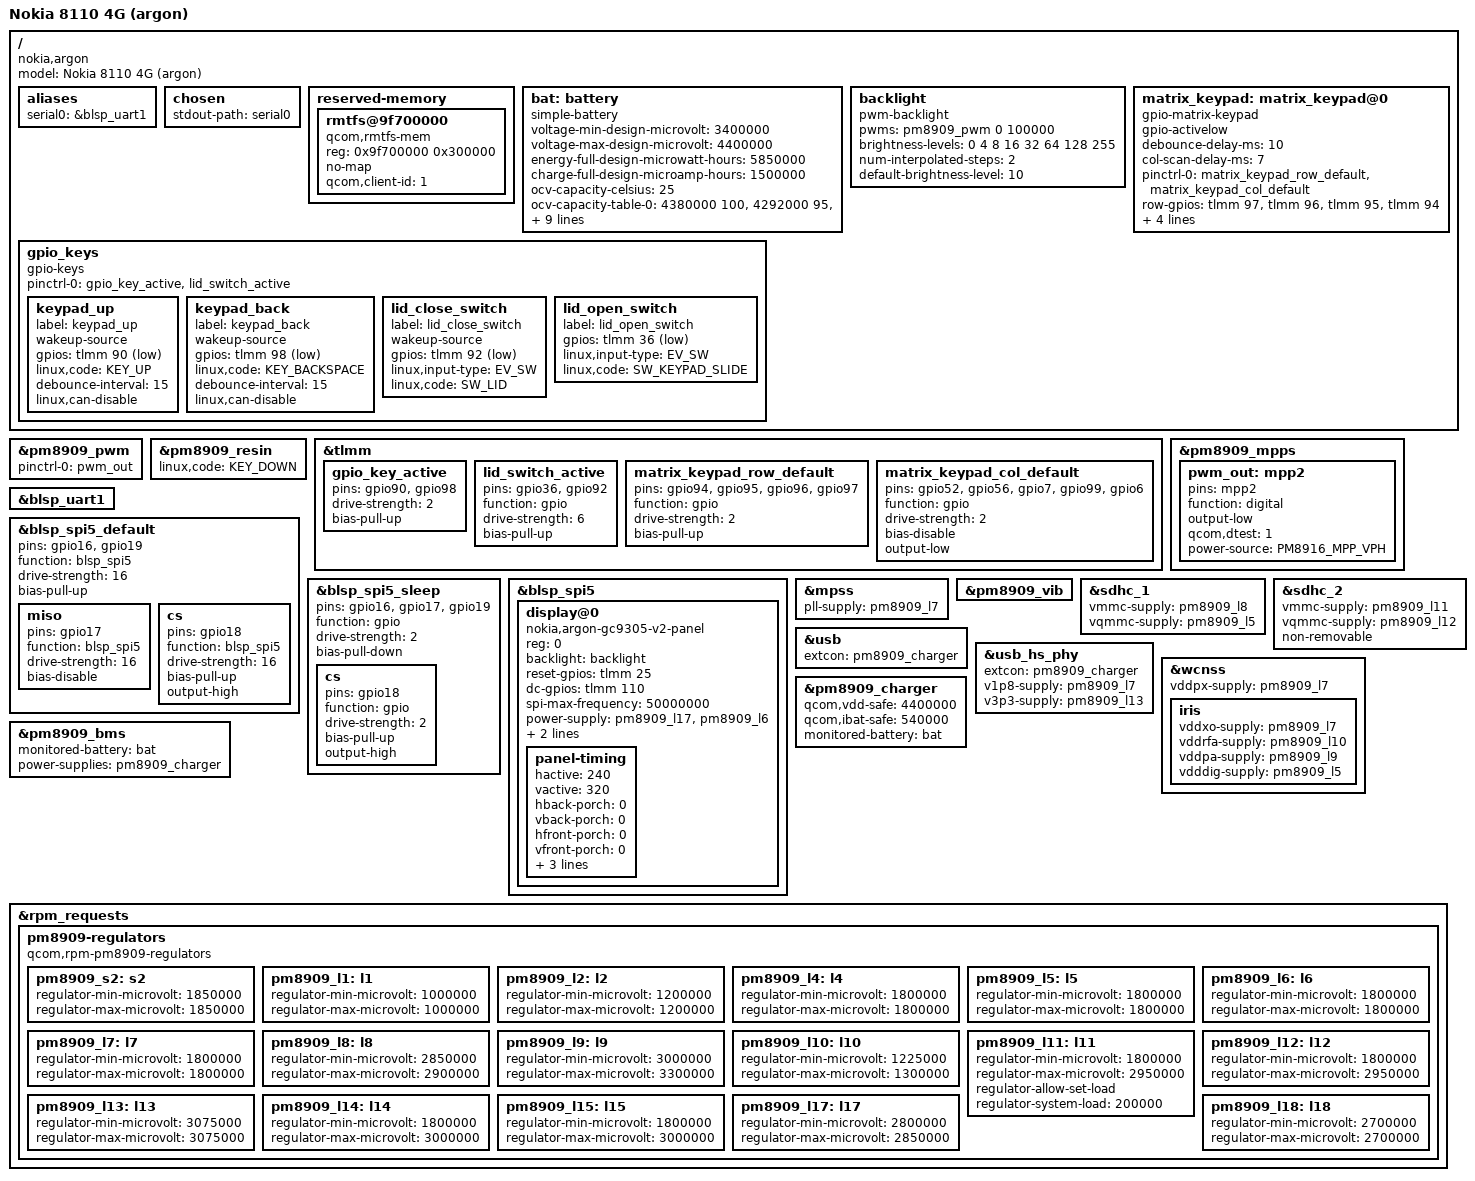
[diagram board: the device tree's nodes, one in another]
// SPDX-License-Identifier: GPL-2.0-only
#include "qcom-msm8905.dtsi"
#include "qcom-pm8909.dtsi"
#include <dt-bindings/sound/qcom,q6afe.h>
#include <dt-bindings/sound/qcom,q6asm.h>
#include <dt-bindings/sound/qcom,q6voice.h>
#include <dt-bindings/pinctrl/qcom,pmic-mpp.h>

/ {
	model = "Nokia 8110 4G (argon)";
	compatible = "nokia,argon", "qcom,msm8909";

	aliases {
		serial0 = &blsp_uart1;
	};

	chosen {
		stdout-path = "serial0";
	};

	reserved-memory {
		/delete-node/ rmtfs@87c00000;
		/* On downstream, this address is set by the bootloader */
		rmtfs@9f700000 {
			compatible = "qcom,rmtfs-mem";
			reg = <0x9f700000 0x300000>;
			no-map;

			qcom,client-id = <1>;
		};
	};

	bat: battery {
		compatible = "simple-battery";
		voltage-min-design-microvolt = <3400000>;
		voltage-max-design-microvolt = <4400000>;
		energy-full-design-microwatt-hours = <5850000>;
		charge-full-design-microamp-hours = <1500000>;

		ocv-capacity-celsius = <25>;
		ocv-capacity-table-0 = <4380000 100>, <4292000 95>,
			<4234000 90>, <4190000 85>, <4158000 80>, <4125000 75>,
			<4090000 70>, <4040000 65>, <3988000 60>, <3950000 55>,
			<3925000 50>, <3880000 45>, <3840000 40>, <3800000 35>,
			<3784000 30>, <3761000 25>, <3743000 20>, <3722000 16>,
			<3702000 13>, <3690000 11>, <3688000 10>, <3687000 9>,
			<3685000 8>, <3683000 7>, <3677000 6>, <3656000 5>,
			<3612000 4>, <3554000 3>, <3462000 2>, <3322000 1>,
			<3000000 0>;
	};

	backlight: backlight {
		compatible = "pwm-backlight";
		pwms = <&pm8909_pwm 0 100000>;

		brightness-levels = <0 4 8 16 32 64 128 255>;
		num-interpolated-steps = <2>;
		default-brightness-level = <10>;
	};

	gpio_keys {
		compatible = "gpio-keys";
		pinctrl-names = "default";
		pinctrl-0 = <&gpio_key_active &lid_switch_active>;

		keypad_up {
			label = "keypad_up";
			wakeup-source;
			gpios = <&tlmm 90 GPIO_ACTIVE_LOW>;
			linux,code = <KEY_UP>;
			debounce-interval = <15>;
			linux,can-disable;
		};

		keypad_back {
			label = "keypad_back";
			wakeup-source;
			gpios = <&tlmm 98 GPIO_ACTIVE_LOW>;
			linux,code = <KEY_BACKSPACE>;
			debounce-interval = <15>;
			linux,can-disable;
		};

		lid_close_switch {
			label = "lid_close_switch";
			wakeup-source;
			gpios = <&tlmm 92 GPIO_ACTIVE_LOW>;
			linux,input-type = <EV_SW>;
			linux,code = <SW_LID>;
		};

		lid_open_switch {
			label = "lid_open_switch";
			gpios = <&tlmm 36 GPIO_ACTIVE_LOW>;
			linux,input-type = <EV_SW>;
			linux,code = <SW_KEYPAD_SLIDE>;
		};
	};

	matrix_keypad: matrix_keypad@0 {
		compatible = "gpio-matrix-keypad";
		gpio-activelow;
		debounce-delay-ms = <10>;
		col-scan-delay-ms = <7>;
		pinctrl-names = "default";
		pinctrl-0 = <&matrix_keypad_row_default &matrix_keypad_col_default>;

		row-gpios = <&tlmm 97 0
			&tlmm 96 0
			&tlmm 95 0
			&tlmm 94 0>;

		col-gpios = <&tlmm 52 0
			&tlmm 56 0
			&tlmm 7 0
			&tlmm 99 0
			&tlmm 6 0>;

		linux,keymap = <
			0x0000003D      /* (0,0) KEY_F3 */
			0x00010002      /* (1,0) KEY_1 */
			0x00020005      /* (2,0) KEY_4 */
			0x00030008      /* (3,0) KEY_7 */
			0x0004020A      /* (4,0) KEY_NUMERIC_STAR */

			0x01000069      /* (0,1) KEY_LEFT */
			0x01010003      /* (1,1) KEY_2 */
			0x01020006      /* (2,1) KEY_5 */
			0x01030009      /* (3,1) KEY_8 */
			0x0104000B      /* (4,1) KEY_0 */

			0x0200000F      /* (0,2) KEY_TAB */
			0x02010004      /* (1,2) KEY_3 */
			0x02020007      /* (2,2) KEY_6 */
			0x0203000A      /* (3,2) KEY_9 */
			0x0204020B      /* (4,2) KEY_NUMERIC_POUND */

			0x0300001C      /* (0,3) KEY_ENTER */
			0x0301006A      /* (1,3) KEY_RIGHT */
			0x0302008B      /* (3,3) KEY_MENU */
			>;
	};
};

&pm8909_pwm {
	status = "okay";
	pinctrl-names = "default";
	pinctrl-0 = <&pwm_out>;
};

&pm8909_resin {
	status = "okay";
	linux,code = <KEY_DOWN>;
};

&tlmm {
	gpio_key_active: gpio_key_active {
		pins = "gpio90", "gpio98";
		drive-strength = <2>;
		bias-pull-up;
	};
	lid_switch_active: lid_switch_active {
		pins = "gpio36", "gpio92";
		function = "gpio";

		drive-strength = <6>;
		bias-pull-up;
	};
	matrix_keypad_row_default: matrix_keypad_row_default {
		pins = "gpio94", "gpio95", "gpio96", "gpio97";
		function = "gpio";

		drive-strength = <2>;
		bias-pull-up;
	};
	matrix_keypad_col_default: matrix_keypad_col_default {
		pins = "gpio52", "gpio56", "gpio7", "gpio99", "gpio6";
		function = "gpio";

		drive-strength = <2>;
		bias-disable;
		output-low;
	};
};

&pm8909_mpps {
	pwm_out: mpp2 {
		pins = "mpp2";
		function = "digital";

		output-low;
		qcom,dtest = <1>;
		power-source = <PM8916_MPP_VPH>;
	};
};

&blsp_uart1 {
	status = "okay";
};

&blsp_spi5_default {
	pins = "gpio16", "gpio19";
	function = "blsp_spi5";

	drive-strength = <16>;
	bias-pull-up;

	miso {
		pins = "gpio17";
		function = "blsp_spi5";

		drive-strength = <16>;
		bias-disable;
	};

	cs {
		pins = "gpio18";
		function = "blsp_spi5";

		drive-strength = <16>;
		bias-pull-up;
		output-high;
	};
};

&blsp_spi5_sleep {
	pins = "gpio16", "gpio17", "gpio19";
	function = "gpio";

	drive-strength = <2>;
	bias-pull-down;

	cs {
		pins = "gpio18";
		function = "gpio";

		drive-strength = <2>;
		bias-pull-up;
		output-high;
	};
};

&blsp_spi5 {
	status = "okay";
	display@0 {
		compatible = "nokia,argon-gc9305-v2-panel", "panel-mipi-dbi-spi";
		reg = <0>;
		backlight = <&backlight>;
		//te-gpios = <&tlmm 24 GPIO_ACTIVE_HIGH>;
		reset-gpios = <&tlmm 25 GPIO_ACTIVE_HIGH>;
		dc-gpios = <&tlmm 110 GPIO_ACTIVE_HIGH>;
		spi-max-frequency = <50000000>;
		power-supply = <&pm8909_l17>, <&pm8909_l6>;
		width-mm = <38>;
		height-mm = <50>;
		panel-timing {
			hactive = <240>;
			vactive = <320>;
			//hback-porch = <12>;
			//vback-porch = <10>;
			//hfront-porch = <12>;
			//vfront-porch = <8>;
			//hsync-len = <4>;
			//vsync-len = <2>;
			hback-porch = <0>;
			vback-porch = <0>;
			hfront-porch = <0>;
			vfront-porch = <0>;
			hsync-len = <0>;
			vsync-len = <0>;
			clock-frequency = <2304000>; // for 30 FPS
		};
	};
};

&mpss {
	status = "okay";
	pll-supply = <&pm8909_l7>;
};

&pm8909_vib {
	status = "okay";
};

&sdhc_1 {
	status = "okay";
	vmmc-supply = <&pm8909_l8>;
	vqmmc-supply = <&pm8909_l5>;
};

&sdhc_2 {
	status = "okay";
	vmmc-supply = <&pm8909_l11>;
	vqmmc-supply = <&pm8909_l12>;
	non-removable;
};

&usb {
	status = "okay";
	extcon = <&pm8909_charger>;
};

&usb_hs_phy {
	extcon = <&pm8909_charger>;
	v1p8-supply = <&pm8909_l7>;
	v3p3-supply = <&pm8909_l13>;
};

&wcnss {
	status = "okay";
	vddpx-supply = <&pm8909_l7>;

	iris {
		vddxo-supply = <&pm8909_l7>;
		vddrfa-supply = <&pm8909_l10>;
		vddpa-supply = <&pm8909_l9>;
		vdddig-supply = <&pm8909_l5>;
	};
};

&pm8909_bms {
	status = "okay";
	monitored-battery = <&bat>;
	power-supplies = <&pm8909_charger>;
};

&pm8909_charger {
	status = "okay";

	qcom,vdd-safe = <4400000>;
	qcom,ibat-safe = <540000>;

	monitored-battery = <&bat>;
};

&rpm_requests {
	pm8909-regulators {
		compatible = "qcom,rpm-pm8909-regulators";

		/* pm8909_s1 is managed by rpmpd (MSM8909_VDDCX) */
		pm8909_s2: s2 {
			regulator-min-microvolt = <1850000>;
			regulator-max-microvolt = <1850000>;
		};

		pm8909_l1: l1 {
			regulator-min-microvolt = <1000000>;
			regulator-max-microvolt = <1000000>;
		};
		pm8909_l2: l2 {
			regulator-min-microvolt = <1200000>;
			regulator-max-microvolt = <1200000>;
		};
		/* pm8909_l3 is managed by rpmpd (MSM8909_VDDMX) */
		pm8909_l4: l4 {
			regulator-min-microvolt = <1800000>;
			regulator-max-microvolt = <1800000>;
		};
		pm8909_l5: l5 {
			regulator-min-microvolt = <1800000>;
			regulator-max-microvolt = <1800000>;
		};
		pm8909_l6: l6 {
			regulator-min-microvolt = <1800000>;
			regulator-max-microvolt = <1800000>;
		};
		pm8909_l7: l7 {
			regulator-min-microvolt = <1800000>;
			regulator-max-microvolt = <1800000>;
		};
		pm8909_l8: l8 {
			regulator-min-microvolt = <2850000>;
			regulator-max-microvolt = <2900000>;
		};
		pm8909_l9: l9 {
			regulator-min-microvolt = <3000000>;
			regulator-max-microvolt = <3300000>;
		};
		pm8909_l10: l10 {
			regulator-min-microvolt = <1225000>;
			regulator-max-microvolt = <1300000>;
		};
		pm8909_l11: l11 {
			regulator-min-microvolt = <1800000>;
			regulator-max-microvolt = <2950000>;
			regulator-allow-set-load;
			regulator-system-load = <200000>;
		};
		pm8909_l12: l12 {
			regulator-min-microvolt = <1800000>;
			regulator-max-microvolt = <2950000>;
		};
		pm8909_l13: l13 {
			regulator-min-microvolt = <3075000>;
			regulator-max-microvolt = <3075000>;
		};
		pm8909_l14: l14 {
			regulator-min-microvolt = <1800000>;
			regulator-max-microvolt = <3000000>;
		};
		pm8909_l15: l15 {
			regulator-min-microvolt = <1800000>;
			regulator-max-microvolt = <3000000>;
		};
		pm8909_l17: l17 {
			regulator-min-microvolt = <2800000>;
			regulator-max-microvolt = <2850000>;
		};
		pm8909_l18: l18 {
			regulator-min-microvolt = <2700000>;
			regulator-max-microvolt = <2700000>;
		};
	};
};
